# USB_USB2SS_GBL_3100C100h register map
Vendor: Texas Instruments
Registers are 32-bit, read-write, reset 0x0 unless marked. A register's access mark holds for its fields unless they carry their own. Offsets are as the file gives them; [hi:lo] are bit positions; lines under a group give offsets from that group; 'fields as' and 'values as' point back to an identical list; <NAME> marks a mode.

## USB2SS_GBL (part 4 of 4)
0x1C0 USB2SS_GBL_GPIPE access not given reset not defined
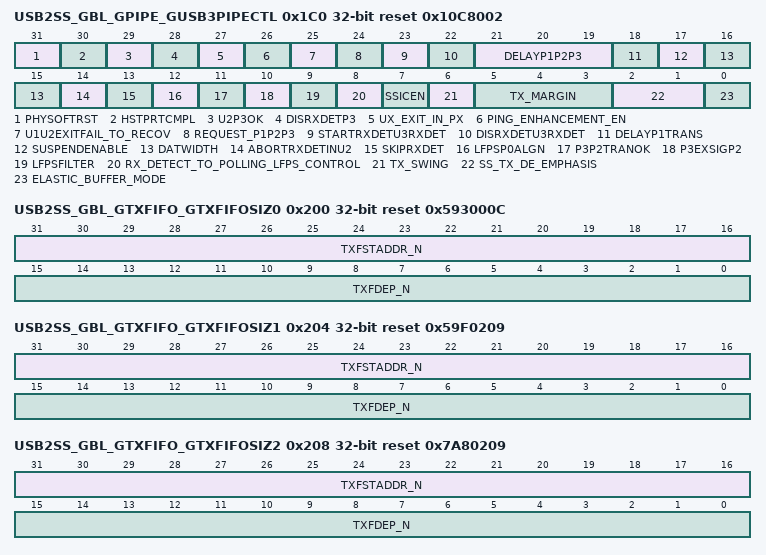
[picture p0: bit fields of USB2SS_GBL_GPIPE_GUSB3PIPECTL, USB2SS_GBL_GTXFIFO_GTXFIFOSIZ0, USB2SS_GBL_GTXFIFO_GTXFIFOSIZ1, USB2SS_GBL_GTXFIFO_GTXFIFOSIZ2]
0x1C0 USB2SS_GBL_GPIPE_GUSB3PIPECTL access per field reset 0x10C8002 — Global USB 3.0 PIPE Control RegisterThe application uses this register to configure the USB3 PHY and PIPE interface.Device-only configuration requires only one register. In Host mode, registers are implemented for each port.For more details on GUSB3PIPECTL(#n) bits, refer to section 'GUSB3PIPECTLn Register' in the User Guide.Note: - GUSB3PIPECTLn registers are not applicable for USB 2.0-only mode.
  [31] PHYSOFTRST rw — USB3 PHY Soft Reset After setting this bit to '1', the software needs to clear this bit. For more information, refer to Figure 'Software Resets and PHY Clock Sequencing and Requirements' in the Databook. Reset Source: rst_mod_g_rst_n
  [30] HSTPRTCMPL rw — HstPrtCmplThis feature tests the PIPE PHY compliance patterns without having to have a test fixture on the USB 3.0 cable. This bit enables placing the SS port link into a compliance state. By default, this bit must be set to 1'b0.In compliance lab testing, the SS port link enters compliance after failing the first polling sequence after power on. Set this bit to 0, when you run compliance tests.The sequence for using this functionality is as follows: - 1. Disconnect any plugged in devices. - 2. Perform USBCMD.HCRST or power-on-chip reset. - 3. Set PORTSC.PLS=0xA. - 4. Set PORTSC.PP=0. - 5. Set GUSB3PIPECTL. HstPrtCmpl=1. This places the link into compliance state.To advance the compliance pattern, follow this sequence [toggle the set GUSB3PIPECTL. HstPrtCmpl]: - 1. Set GUSB3PIPECTL.HstPrtCmpl=0. - 2. Set GUSB3PIPECTL.HstPrtCmpl=1. This advances the link to the next compliance pattern.To exit from the compliance state perform USBCMD.HCRST or power-on-chip reset. Reset Source: rst_mod_g_rst_n
  [29] U2P3OK rw — P3 OK for SSInactive [SSIP3ok] - 0: During link state SS.Inactive, put PHY in P2 [Default] - 1: During link state SS.Inactive, put PHY in P3. Reset Source: rst_mod_g_rst_n
  [28] DISRXDETP3 rw — Disabled receiver detection in P3 [DisRxDetP3] - 0: If PHY is in P3 and controller needs to perform receiver detection, The controller performs receiver detection in P3. [Default] - 1: If PHY is in P3 and controller needs to perform receiver detection, The controller changes the PHY power state to P2 and then performs receiver detection. After receiver detection, the cores changes PHY power state to P3. Reset Source: rst_mod_g_rst_n
  [27] UX_EXIT_IN_PX rw — Ux Exit in Px [Ux_exit_in_Px] - 0: The controller does U1/U2/U3 exit in PHY power state P0 [default behavior]. - 1: The controller does U1/U2/U3 exit in PHY power state P1/P2/P3 respectively. Note: This bit is used by third-party SS PHY. It must be set to '0' for Synopsys PHY. Reset Source: rst_mod_g_rst_n
  [26] PING_ENHANCEMENT_EN rw — Ping Enhancement Enable [ping_enhancement_en]When set, the Downstream port U1 ping receive timeout becomes 500 ms instead of 300 ms. Minimum Ping.LFPS receive duration is 8 ns [one mac3_clk]. This field is valid for the downstream port only. Note: This bit is used by third-party SS PHY. It must be set to '0' for Synopsys PHY. Reset Source: rst_mod_g_rst_n
  [25] U1U2EXITFAIL_TO_RECOV rw — U1U2exitfail to Recovery [u1u2exitfail_to_recov]When set, and U1/U2 LFPS handshake fails, the LTSSM transitions from U1/U2 to Recovery instead of SS Inactive. If Recovery fails, then the LTSSM can enter SS.Inactive. This is an enhancement only. It prevents interoperability issue if the remote link does not do proper handshake. Reset Source: rst_mod_g_rst_n
  [24] REQUEST_P1P2P3 rw — Always Request P1/P2/P3 for U1/U2/U3 [request_p1p2p3]When set, the controller always requests PHY power change from P0 to P1/P2/P3 during U0 to U1/U2/U3 transition.If this bit is 0, and immediate Ux exit [remotely initiated, or locally initiated] happens, the controller does not request P1/P2/P3 power state change.Note: This bit must be set to '1' for Synopsys PHY. For third-party SS PHY, check with your PHY vendor. Reset Source: rst_mod_g_rst_n
  [23] STARTRXDETU3RXDET wo — Start Receiver Detection in U3/Rx.Detect [StartRxdetU3RxDet]If DWC_USB3_GUSB3PIPECTL_INIT[22] is set, and the link is in either U3 or Rx.Detect state, the controller starts receiver detection on the rising edge of this bit. This can only be used for Downstream ports. This bit must be set to '0' for Upstream ports. This feature must not be enabled for normal operation. If have to use this feature, contact Synopsys. Reset Source: rst_mod_g_rst_n
  [22] DISRXDETU3RXDET rw — Disable Receiver Detection in U3/Rx.DetWhen set, the controller does not handle receiver detection in either U3 or Rx.Detect states. DWC_USB3_GUSB3PIPECTL_INIT[23] must be used to start receiver detection manually. This bit can only be used for the downstream port. This bit must be set to '0' for Upstream ports. This feature must not be enabled for normal operation. If you have to use this feature, contact Synopsys. Reset Source: rst_mod_g_rst_n
  [21:19] DELAYP1P2P3 rw — Delay P1P2P3Delay P0 to P1/P2/P3 request when entering U1/U2/U3 until [DWC_USB3_GUSB3PIPECTL_INIT[21:19]*8] 8B10B error occurs, or Pipe3_RxValid drops to 0.DWC_USB3_GUSB3PIPECTL_INIT[18] must be 1 to enable this functionality. Reset Source: rst_mod_g_rst_n
  [18] DELAYP1TRANS rw — Delay PHY power change from P0 to P1/P2/P3 when link state changing from U0 to U1/U2/U3 respectively. - 1'b1: When entering U1/U2/U3, delay the transition to P1/P2/P3 until the pipe3 signals, Pipe3_RxElecIdle is 1 and pipe3_RxValid is 0 - 1'b0: When entering U1/U2/U3, transition to P1/P2/P3 without checking for Pipe3_RxElecIdle and pipe3_RxValid.Note: - If you are using Synopsys PHY, contact Synopsys Customer Support for recommendation on setting this bit because it is node dependent. - If you are using a third-party SS PHY, check with your PHY vendor for recommendation on setting this bit. Reset Source: rst_mod_g_rst_n
  [17] SUSPENDENABLE rw — Suspend USB3.0 SS PHY [Suspend_en]When set, and if Suspend conditions are valid, the USB 3.0 PHY enters Suspend mode.For DRD configurations, it is recommended that this bit is set to '0' during coreConsultant configuration. If it is set to '1', then the application must clear this bit after power-on reset. Application needs to set it to '1' after the controller initialization is completed.For all other configurations, this bit can be set to '1' during controller configuration. Reset Source: rst_mod_g_rst_n
  [16:15] DATWIDTH ro — PIPE Data Width [DatWidth] - 2'b00: 32 bits - 2'b01: 16 bitsOne clock after reset, these bits receive the value seen on the pipe3_DataBusWidth. The simulation testbench uses the coreConsultant parameter to configure the VIP. These bits in the coreConsultant parameter must match your PHY data width and the pipe3_DataBusWidth port.Note: 8-bit data width is not supported. Reset Source: rst_mod_g_rst_n
  [14] ABORTRXDETINU2 rw — Abort Rx Detect in U2 [AbortRxDetInU2]When set and the link state is U2, the controller will abort receiver detection if it receives U2 exit LFPS from the remote link partner. This bit is for the downstream port only.Note: This bit is used by third-party SS PHY. It must be set to '0' for Synopsys PHY. Reset Source: rst_mod_g_rst_n
  [13] SKIPRXDET rw — Skip Rx Detect:When set, the controller skips Rx Detection if pipe3_RxElecIdle is low. Skip is defined as waiting for the appropriate timeout, then repeating the operation. Reset Source: rst_mod_g_rst_n
  [12] LFPSP0ALGN rw — LFPS P0 Align:When set, - The controller deasserts LFPS transmission on the clock edge that it requests Phy power state 0 when exiting U1, U2, or U3 low power states. Otherwise, LFPS transmission is asserted one clock earlier. - The controller requests symbol transmission two pipe3_rx_pclks periods after the PHY asserts PhyStatus as a result of the PHY switching from P1 or P2 state to P0 state.Currently, this bit is only used in USB 3.0 HUB with Synopsys PHY. For other USB 3.0 Host, Device, and DRD cores, this bit is not required. Reset Source: rst_mod_g_rst_n
  [11] P3P2TRANOK rw — P3 P2 Transitions OK [P3P2TranOK]When set, the controller transitions directly from Phy power state P2 to P3 or from state P3 to P2.When not set, P0 is always entered as an intermediate state during transitions between P2 and P3, as defined in the PIPE3 Specification.According to the PIPE3 Specification, any direct transition between P3 and P2 is illegal.Note: This bit is used by third-party SS PHY. It must be set to '0' for Synopsys PHY. Reset Source: rst_mod_g_rst_n
  [10] P3EXSIGP2 rw — P3 Exit Signal in P2 [P3ExSigP2]When this bit is set, the controller always changes the PHY power state to P2, before attempting a U3 exit handshake. This bit is used only for some non-Synopsys PHYs that cannot do LFPS in P3.Note: This bit is used by third-party SS PHY. It must be set to '0' for Synopsys PHY. Reset Source: rst_mod_g_rst_n
  [9] LFPSFILTER rw — LFPS Filter [LFPSFilt]When set, filter LFPS reception with pipe3_RxValid in PHY power state P0, that is, ignore LFPS reception from the PHY unless both pipe3_Rxelecidle and pipe3_RxValid are deasserted. Reset Source: rst_mod_g_rst_n
  [8] RX_DETECT_TO_POLLING_LFPS_CONTROL rw — RX_DETECT to Polling.LFPS Control - 1'b0 [Default]: Enables a 400us delay to start Polling LFPS after RX_DETECT. This allows VCM offset to settle to a proper level. - 1'b1: Disables the 400us delay to start Polling LFPS after RX_DETECT.During controller certification with third party PHY it is observed that the PHY is not able to meet the Tx AC common mode voltage active [VTX-CM-ACPP_ACTIVE <100mv] if the link starts polling within 80us from the time rx.detect is performed.To meet this VTX-CM-ACPP_ACTIVE specification, the polling must be delayed further. If the PHY does not have issue then they can set this bit to 1 which allows polling to start within 80us. Reset Source: rst_mod_g_rst_n
  [7] SSICEN rw — This field is not used. Reset Source: rst_mod_g_rst_n
  [6] TX_SWING rw — Tx Swing [TxSwing]Refer to the PIPE3 specification. Reset Source: rst_mod_g_rst_n
  [5:3] TX_MARGIN rw — Tx Margin[2:0] [TxMargin]Refer to Table 5-3 of the PIPE3 Specification. Reset Source: rst_mod_g_rst_n
  [2:1] SS_TX_DE_EMPHASIS rw — Tx Deemphasis [TxDeemphasis]The value driven to the PHY is controlled by the LTSSM during USB3 Compliance mode.[Refer to Table 5-3 of the PIPE3 specification.] Reset Source: rst_mod_g_rst_n
  [0] ELASTIC_BUFFER_MODE rw — Elastic Buffer Mode [ElasticBufferMode][Refer to Table 5-3 of the PIPE3 specification.] Reset Source: rst_mod_g_rst_n
0x200 USB2SS_GBL_GTXFIFO access not given reset not defined
0x200 USB2SS_GBL_GTXFIFO_GTXFIFOSIZ0 reset 0x593000C — Global Transmit FIFO Size RegisterThis register specifies the RAM start address and depth (both in MDWIDTH-bit words) for each implemented TxFIFO. The number of TxFIFOs depends on the configuration parameters including the number of Device IN Endpoints, number of Host Bus Instances, and presence of Debug Capability.The register default values for each mode are assigned in coreConsultant based on the maximum packet size, number of packets to be buffered, speed of host bus instance, bus latency, and mode of operation (host, device, or, DBC). Upon reset and mode transitions, hardware automatically programs these registers to the default values. Consequently, there is typically no need for the software to modify the pre-defined default values.For the debug capability mode, the currently mapped EP0 IN and EP1 IN TxFIFO numbers can be read from the GFIFOPRIDBC register. For more details on the usage of the GTXFIFOSIZn and GRXFIFOSIZn registers for different modes of operation, refer to 'Memory Requirements' chapter in the Databook.
  [31:16] TXFSTADDR_N — Transmit FIFOn RAM Start Address This field contains the memory start address for TxFIFOn in MDWIDTH-bit words. Reset Source: rst_mod_g_rst_n
  [15:0] TXFDEP_N — TxFIFO Depth This field contains the depth of TxFIFOn in MDWIDTH-bit words. - Minimum value: 32 - Maximum value: 32,768For more information, see 'Integrating the Controller' chapter in the User Guide. Reset Source: rst_mod_g_rst_n
0x204 USB2SS_GBL_GTXFIFO_GTXFIFOSIZ1 reset 0x59F0209 — Register GTXFIFOSIZ 1
  [31:16] TXFSTADDR_N — Transmit FIFOn RAM Start Address This field contains the memory start address for TxFIFOn in MDWIDTH-bit words. Reset Source: rst_mod_g_rst_n
  [15:0] TXFDEP_N — TXFDEP_N Reset Source: rst_mod_g_rst_n
0x208 USB2SS_GBL_GTXFIFO_GTXFIFOSIZ2 reset 0x7A80209 — Transmit FIFOn RAM Start Address This field contains the memory start address for TxFIFOn in MDWIDTH-bit words.
  fields as USB2SS_GBL_GTXFIFO_GTXFIFOSIZ0
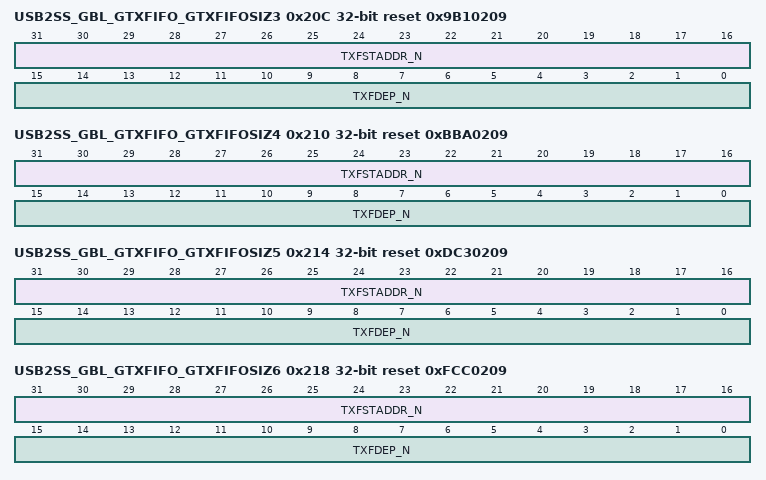
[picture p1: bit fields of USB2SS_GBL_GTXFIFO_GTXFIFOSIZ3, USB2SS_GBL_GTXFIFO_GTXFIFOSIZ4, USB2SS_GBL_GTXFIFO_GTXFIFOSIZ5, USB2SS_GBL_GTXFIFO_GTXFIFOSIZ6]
0x20C USB2SS_GBL_GTXFIFO_GTXFIFOSIZ3 reset 0x9B10209 — Register GTXFIFOSIZ 3
  [31:16] TXFSTADDR_N — Transmit FIFOn RAM Start AddressThis field contains the memory start address for TxFIFOn in MDWIDTH-bit words. Reset Source: rst_mod_g_rst_n
  [15:0] TXFDEP_N — TXFDEP_N: TxFIFO Depth [TxFDep_n]This field contains the depth of TxFIFOn in MDWIDTH-bit words. - Minimum value: 32 - Maximum value: 32,768For more information, see 'Integrating the Controller' chapter in the User Guide. Reset Source: rst_mod_g_rst_n
0x210 USB2SS_GBL_GTXFIFO_GTXFIFOSIZ4 reset 0xBBA0209 — Register GTXFIFOSIZ 4
  [31:16] TXFSTADDR_N — TXFSTADDR_N Reset Source: rst_mod_g_rst_n
  [15:0] TXFDEP_N — TXFDEP_N: TxFIFO Depth [TxFDep_n]This field contains the depth of TxFIFOn in MDWIDTH-bit words. - Minimum value: 32 - Maximum value: 32,768For more information, see 'Integrating the Controller' chapter in the User Guide. Reset Source: rst_mod_g_rst_n
0x214 USB2SS_GBL_GTXFIFO_GTXFIFOSIZ5 reset 0xDC30209 — Register GTXFIFOSIZ 5
  [31:16] TXFSTADDR_N — Transmit FIFOn RAM Start Address Reset Source: rst_mod_g_rst_n
  [15:0] TXFDEP_N — TxFIFO Depth This field contains the depth of TxFIFOn in MDWIDTH-bit words. - Minimum value: 32 - Maximum value: 32,768For more information, see 'Integrating the Controller' chapter in the User Guide. Reset Source: rst_mod_g_rst_n
0x218 USB2SS_GBL_GTXFIFO_GTXFIFOSIZ6 reset 0xFCC0209 — Register GTXFIFOSIZ 6
  fields as USB2SS_GBL_GTXFIFO_GTXFIFOSIZ0
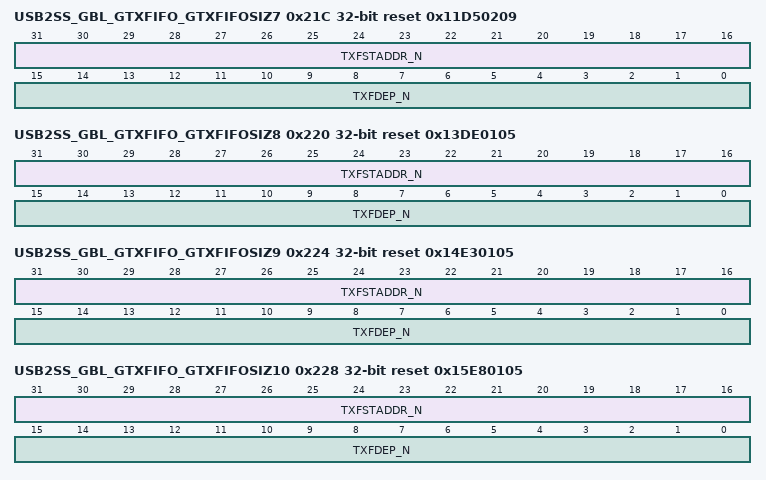
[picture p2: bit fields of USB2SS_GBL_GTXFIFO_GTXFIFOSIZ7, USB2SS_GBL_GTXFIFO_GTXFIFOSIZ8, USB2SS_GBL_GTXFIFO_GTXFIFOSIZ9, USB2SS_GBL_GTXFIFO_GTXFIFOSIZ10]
0x21C USB2SS_GBL_GTXFIFO_GTXFIFOSIZ7 reset 0x11D50209 — Register GTXFIFOSIZ 7
  [31:16] TXFSTADDR_N — Transmit FIFOn RAM Start Address This field contains the memory start address for TxFIFOn in MDWIDTH-bit words. Reset Source: rst_mod_g_rst_n
  [15:0] TXFDEP_N — TXFDEP_NThis field contains the depth of TxFIFOn in MDWIDTH-bit words. - Minimum value: 32 - Maximum value: 32,768For more information, see 'Integrating the Controller' chapter in the User Guide. Reset Source: rst_mod_g_rst_n
0x220 USB2SS_GBL_GTXFIFO_GTXFIFOSIZ8 reset 0x13DE0105 — Register GTXFIFOSIZ 8
  fields as USB2SS_GBL_GTXFIFO_GTXFIFOSIZ0
0x224 USB2SS_GBL_GTXFIFO_GTXFIFOSIZ9 reset 0x14E30105 — Register GTXFIFOSIZ 9
  fields as USB2SS_GBL_GTXFIFO_GTXFIFOSIZ0
0x228 USB2SS_GBL_GTXFIFO_GTXFIFOSIZ10 reset 0x15E80105 — GTXFIFOSIZ 10
  [31:16] TXFSTADDR_N — Transmit FIFOn RAM Start Address This field contains the memory start address for TxFIFOn in MDWIDTH-bit words. Reset Source: rst_mod_g_rst_n
  [15:0] TXFDEP_N — TXFDEP_N: TxFIFO Depth [TxFDep_n]This field contains the depth of TxFIFOn in MDWIDTH-bit words. - Minimum value: 32 - Maximum value: 32,768For more information, see 'Integrating the Controller' chapter in the User Guide. Reset Source: rst_mod_g_rst_n
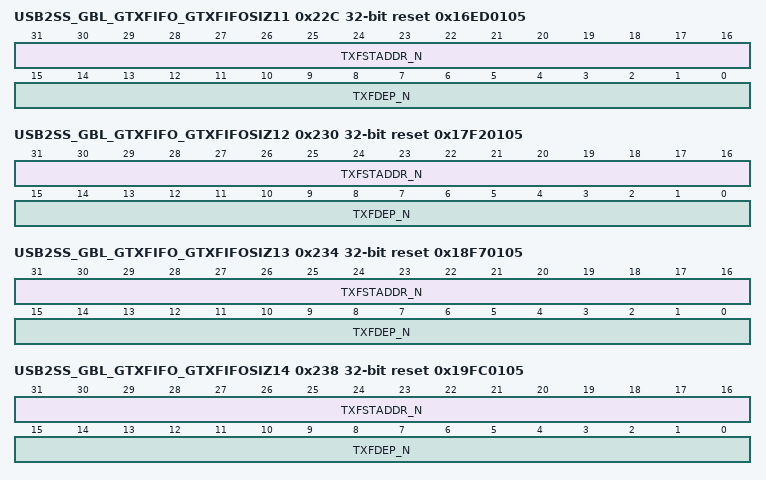
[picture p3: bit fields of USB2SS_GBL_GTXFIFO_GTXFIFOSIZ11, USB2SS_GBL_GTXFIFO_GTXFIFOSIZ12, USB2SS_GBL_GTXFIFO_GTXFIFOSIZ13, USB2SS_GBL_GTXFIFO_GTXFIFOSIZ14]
0x22C USB2SS_GBL_GTXFIFO_GTXFIFOSIZ11 reset 0x16ED0105 — Register GTXFIFOSIZ 11
  [31:16] TXFSTADDR_N — Transmit FIFOn RAM Start AddressThis field contains the memory start address for TxFIFOn in MDWIDTH-bit words. Reset Source: rst_mod_g_rst_n
  [15:0] TXFDEP_N — TxFIFO Depth This field contains the depth of TxFIFOn in MDWIDTH-bit words. - Minimum value: 32 - Maximum value: 32,768For more information, see 'Integrating the Controller' chapter in the User Guide. Reset Source: rst_mod_g_rst_n
0x230 USB2SS_GBL_GTXFIFO_GTXFIFOSIZ12 reset 0x17F20105 — GTXFIFOSIZ 12
  fields as USB2SS_GBL_GTXFIFO_GTXFIFOSIZ0
0x234 USB2SS_GBL_GTXFIFO_GTXFIFOSIZ13 reset 0x18F70105 — Register GTXFIFOSIZ 13
  fields as USB2SS_GBL_GTXFIFO_GTXFIFOSIZ1
0x238 USB2SS_GBL_GTXFIFO_GTXFIFOSIZ14 reset 0x19FC0105 — Register GTXFIFOSIZ 14
  fields as USB2SS_GBL_GTXFIFO_GTXFIFOSIZ1
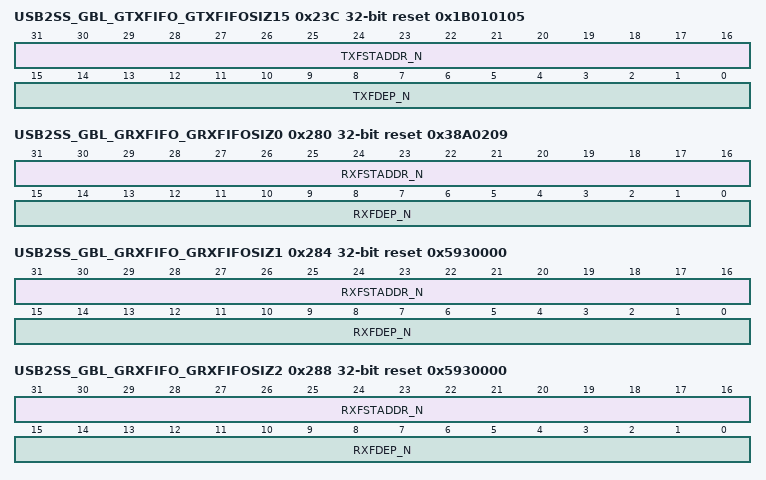
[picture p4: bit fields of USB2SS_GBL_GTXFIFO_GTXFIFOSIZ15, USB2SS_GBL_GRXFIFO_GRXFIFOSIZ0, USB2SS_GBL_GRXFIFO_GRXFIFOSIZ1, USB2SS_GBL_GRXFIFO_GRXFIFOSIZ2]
0x23C USB2SS_GBL_GTXFIFO_GTXFIFOSIZ15 reset 0x1B010105 — Register GTXFIFOSIZ 15
  [31:16] TXFSTADDR_N — TXFSTADDR_N Reset Source: rst_mod_g_rst_n
  [15:0] TXFDEP_N — TXFDEP_N Reset Source: rst_mod_g_rst_n
0x280 USB2SS_GBL_GRXFIFO access not given reset not defined
0x280 USB2SS_GBL_GRXFIFO_GRXFIFOSIZ0 reset 0x38A0209 — Global Receive FIFO Size RegisterThis register specifies the RAM start address and depth (both in MDWIDTH-bit words) for each implemented RxFIFO. The number of RxFIFOs depends on the configuration parameters including the number of Host Bus Instances and presence of Debug Capability. device mode requires only one RxFIFO.The register default values for each mode are assigned in coreConsultant based on the maximum packet size, number of packets to be buffered, speed of the host bus instance, bus latency, and mode of operation (host, device, or DBC). Upon reset and mode transitions, hardware automatically programs these registers to the default values. Consequently, there is typically no need for the software to modify the pre-defined default values.For the debug capability mode, the currently mapped RxFIFO number can be read from the GFIFOPRIDBC register.For more details on the usage of the GTXFIFOSIZn and GRXFIFOSIZn registers for different modes of operation, refer to 'Memory Requirements' chapter in the Databook.
  [31:16] RXFSTADDR_N — RxFIFOn RAM Start Address [RxFStAddr_n]This field contains the memory start address for RxFIFOn in MDWIDTH-bit words. Reset Source: rst_mod_g_rst_n
  [15:0] RXFDEP_N — RxFIFO Depth [RxFDep_n]This field contains the depth of RxFIFOn in MDWIDTH-bit words. - Minimum value: 32 - Maximum value: 16,384 Reset Source: rst_mod_g_rst_n
0x284 USB2SS_GBL_GRXFIFO_GRXFIFOSIZ1 reset 0x5930000 — Register
  [31:16] RXFSTADDR_N — RXFSTADDR_N Reset Source: rst_mod_g_rst_n
  [15:0] RXFDEP_N — RxFIFO Depth This field contains the depth of RxFIFOn in MDWIDTH-bit words. - Minimum value: 32 - Maximum value: 16,384 Reset Source: rst_mod_g_rst_n
0x288 USB2SS_GBL_GRXFIFO_GRXFIFOSIZ2 reset 0x5930000 — Register
  [31:16] RXFSTADDR_N — RAM Start Address This field contains the memory start address for RxFIFOn in MDWIDTH-bit words. Reset Source: rst_mod_g_rst_n
  [15:0] RXFDEP_N — RxFIFO Depth This field contains the depth of RxFIFOn in MDWIDTH-bit words. - Minimum value: 32 - Maximum value: 16,384 Reset Source: rst_mod_g_rst_n
0x300 USB2SS_GBL_GEVNT_GEVNTADRLO_j — Global Event Buffer Address (Low) RegisterThis is an alternate register for the GEVNTADRn register.
  [31:0] EVNTADRLO — Event Buffer Address [EvntAdrLo]Holds the lower 32 bits of start address of the external memory for the Event Buffer. During operation, hardware does not update this address. Reset Source: rst_mod_g_rst_n
0x304 USB2SS_GBL_GEVNT_GEVNTADRHI_j — Global Event Buffer Address (High) RegisterThis is an alternate register for the GEVNTADRn register.
  [31:0] EVNTADRHI — Event Buffer Address [EvntAdrHi]Holds the higher 32 bits of start address of the external memory for the Event Buffer. During operation, hardware does not update this address. Reset Source: rst_mod_g_rst_n
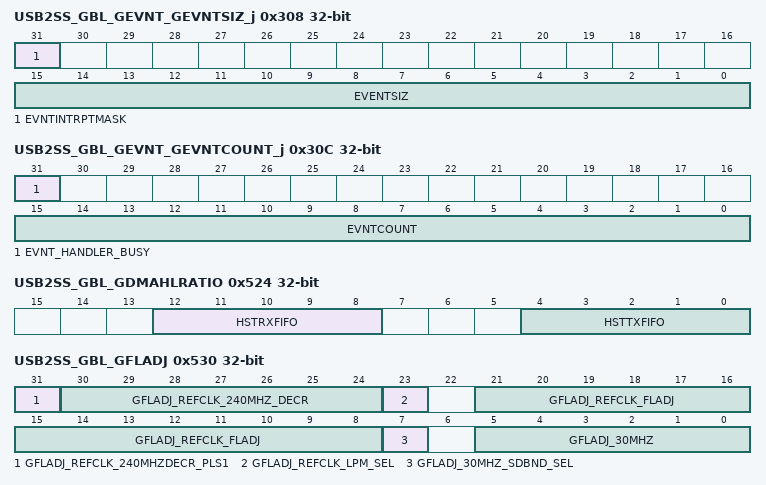
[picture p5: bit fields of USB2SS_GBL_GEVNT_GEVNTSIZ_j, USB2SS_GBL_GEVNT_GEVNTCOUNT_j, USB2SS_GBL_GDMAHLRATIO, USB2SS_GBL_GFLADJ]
0x308 USB2SS_GBL_GEVNT_GEVNTSIZ_j — Global Event Buffer Size RegisterThis register holds the Event Buffer Size and the Event Interrupt Mask bit. During power-on initialization, software must initialize the size with the number of bytes allocated for the Event Buffer. The Event Interrupt Mask will mask the interrupt, but events are still queued. After configuration, software must preserve the Event Buffer Size value when changing the Event Interrupt Mask.
  [31] EVNTINTRPTMASK — Event Interrupt Mask [EvntIntMask].When set to '1', this prevents the interrupt from being generated. However, even when the mask is set, the events are queued. Reset Source: rst_mod_g_rst_n
  [15:0] EVENTSIZ — Event Buffer Size in bytes [EVNTSiz]Holds the size of the Event Buffer in bytes. must be a multiple of four. This is programmed by software once during initialization.The minimum size of the event buffer is 32 bytes. Reset Source: rst_mod_g_rst_n
0x30C USB2SS_GBL_GEVNT_GEVNTCOUNT_j — Global Event Buffer Count RegisterThis register holds the number of valid bytes in the Event Buffer. During initialization, software must initialize the count by writing 0 to the Event Count field. Each time the hardware writes a new event to the Event Buffer, it increments this count. Most events are four bytes, but some events may span over multiple four byte entries. Whenever the count is greater than zero and if enabled, conditions for interrupt moderation are satisfied, the hardware raises the corresponding interrupt line (depending on the EvntIntMask bit in the GEVNTSIZn register). On an interrupt, software processes one or more events out of the Event Buffer. Afterwards, software must write the Event Count field with the number of bytes it processed. If Interrupt Moderation is enabled, then software needs to clear EVNT_HANDLER_BUSY bit. Clock crossing delays may result in the continuous assertion of the interrupt after software acknowledges the last event. Therefore, when the interrupt line is asserted, software must read the GEVNTCOUNT register and only process events if the GEVNTCOUNT is greater than 0.
  [31] EVNT_HANDLER_BUSY — Event Handler BusyDevice software event handler busy indication. The controller sets this bit when the interrupt line is asserted due to pending events. Software clears this bit [with 1'b1] when it has finished processing the events [along with updating the EVNTCOUNT in this register]. The controller does not raise the interrupt line for a new event unless this bit is cleared.Note: When Interrupt moderation is disabled [that is, DEVICE_IMODI = 0], this bit is ignored. Reset Source: rst_mod_g_rst_n
  [15:0] EVNTCOUNT — Event Count [EVNTCount]When read, returns the number of valid events in the Event Buffer [in bytes].When written, hardware decrements the count by the value written.When Interrupt moderation is enabled [that is, DEVICE_IMODI!= 0], the interrupt line gets de-asserted when the first write happens on this register to decrement the count. When Interrupt moderation is disabled [that is, DEVICE_IMODI = 0], the Interrupt line continues to get asserted until the event count becomes zero [no-moderation behavior]. Reset Source: rst_mod_g_rst_n
0x500 USB2SS_GBL_GHWPARAMS8 ro reset 0x660 — Global Hardware Parameters Register 8This register contains the hardware configuration options that you can select in the coreConsultant GUI. For a description of each parameter, refer to the 'Parameter Descriptions' chapter in the Databook. This information is also available in coreConsultant by right-clicking the parameter label and selecting 'What's This' or by clicking the Help tab. Note: Some of the global hardware parameters are not currently modifiable in coreConsultant. These settings are in the <workspace>/src/DWC_usb3_params.v file. you must not change them.
  [31:0] GHWPARAMS8_32_0 — DWC_USB3_DCACHE_DEPTH_INFO Reset Source: rst_mod_g_rst_n
0x50C USB2SS_GBL_GUCTL3 — Global User Control Register 3This register provides a few options for the software to control the controller behavior in the Host mode. Most of the options are used to improve host inter-operability with different devices.
  [16] SCH_PING_EARLY — Enable SuperSpeed Ping Transaction Packet scheduling early in the microframe.This bit is valid in Host mode only. Reset Source: rst_mod_g_rst_n
0x510 USB2SS_GBL_GTXFIFOPRIDEV — Global Device TX FIFO DMA Priority RegisterThis register specifies the relative DMA priority level among the Device TXFIFOs (one per IN endpoint). Each register bit[n] controls the priority (1: high, 0: low) of each TXFIFO[n]. When multiple TXFIFOs compete for DMA service at a given time (that is, multiple TXQs contain TX DMA requests and their corresponding TXFIFOs have space available), the TX DMA arbiter grants access on a packet-basis in the following manner: - 1. High-priority TXFIFOs are granted access using round-robin arbitration - 2. Low-priority TXFIFOs are granted access using round-robin arbitration only after the high-priority TXFIFOs have no further processing to do (that is, either the TXQs are empty or the corresponding TXFIFOs are full).For scatter-gather packets, the arbiter grants successive DMA requests to the same FIFO until the entire packet is completed.When configuring periodic IN endpoints, software must set register bit[n]=1, where n is the TXFIFO assignment. This ensures that the DMA for isochronous or interrupt IN endpoints are prioritized over bulk or control IN endpoints.This register is present only when the controller is configured to operate in the device mode (includes DRD mode). The register size corresponds to the number of Device IN endpoints.Note - Since the device mode uses only one RXFIFO, there is no Device RXFIFO DMA Priority Register.
  [15:0] GTXFIFOPRIDEV — Device TxFIFO priority Reset Source: rst_mod_g_rst_n
0x518 USB2SS_GBL_GTXFIFOPRIHST — Global Host TX FIFO DMA Priority RegisterThis register specifies the relative DMA priority level among the Host TXFIFOs (one per USB bus instance) within the associated speed group (SS or HS/FSLS). Each register bit[n] controls the priority (1: high, 0: low) of TXFIFO[n] within a speed group. When multiple TXFIFOs compete for DMA service at a given time (i.e., multiple TXQs contain TX DMA requests and their corresponding TXFIFOs have space available), the TX DMA arbiter grants access on a packet-basis in the following manner: - 1. Among the FIFOs in the same speed group (SS or HS/FSLS): a. High-priority TXFIFOs are granted access using round-robin arbitration b. Low-priority TXFIFOs are granted access using round-robin arbitration only after the high-priority TXFIFOs have no further processing to do (that is, either the TXQs are empty or the corresponding TXFIFOs are full). - 2. The TX DMA arbiter prioritizes the SS speed group or HS/FSLS speed group according to the ratio programmed in the GDMAHLRATIO register.For scatter-gather packets, the arbiter grants successive DMA requests to the same FIFO until the entire packet is completed.This register is present only when the controller is configured to operate in the host mode (includes DRD mode). The register size corresponds to the number of configured USB bus instances. for example, in the default configuration, there are 3 USB bus instances (1 SS, 1 HS, and 1 FSLS).
  [2:0] GTXFIFOPRIHST — Host TxFIFO priority Reset Source: rst_mod_g_rst_n
0x51C USB2SS_GBL_GRXFIFOPRIHST — Global Host RX FIFO DMA Priority RegisterThis register specifies the relative DMA priority level among the Host RXFIFOs (one per USB bus instance) within the associated speed group (SS or HS/FSLS). Each register bit[n] controls the priority (1: high, 0: low) of RXFIFO[n] within a speed group. When multiple RXFIFOs compete for DMA service at a given time (i.e., multiple RXQs contain RX DMA requests and their corresponding RXFIFOs have data available), the RX DMA arbiter grants access on a packet-basis in the following manner: - 1. Among the FIFOs in the same speed group (SS or HS/FSLS): a. High-priority RXFIFOs are granted access using round-robin arbitration b. Low-priority RXFIFOs are granted access using round-robin arbitration only after high-priority RXFIFOs have no further processing to do (that is, either the RXQs are empty or the corresponding RXFIFOs do not have the required data). - 2. The RX DMA arbiter prioritizes the SS speed group or HS/FSLS speed group according to the ratio programmed in the GDMAHLRATIO register.For scatter-gather packets, the arbiter grants successive DMA requests to the same FIFO until the entire packet is completed.This register is present only when the controller is configured to operate in the host mode (includes DRD mode). The register size corresponds to the number of configured USB bus instances. for example, in the default configuration, there are 3 USB bus instances (1 SS, 1 HS, and 1 FSLS).
  [2:0] GRXFIFOPRIHST — Host RxFIFO priority Reset Source: rst_mod_g_rst_n
0x524 USB2SS_GBL_GDMAHLRATIO — Global Host FIFO DMA High-Low Priority Ratio RegisterThis register specifies the relative priority of the SS FIFOs with respect to the HS/FSLS FIFOs. The DMA arbiter prioritizes the HS/FSLS round-robin arbiter group every DMA High-Low Priority Ratio grants as indicated in the register separately for TX and RX.To illustrate, consider that all FIFOs are requesting access simultaneously, and the ratio is 4. SS gets priority for 4 packets, HS/FSLS gets priority for 1 packet, SS gets priority for 4 packets, HS/FSLS gets priority for 1 packet, and so on.If FIFOs from both speed groups are not requesting access simultaneously then, - if SS got grants 4 out of the last 4 times, then HS/FSLS get the priority on any future request. - if HS/FSLS got the grant last time, SS gets the priority on the next request. - if there is a valid request on either SS or HS/FSLS, a grant is always awarded. there is no idle.This register is present if the controller is configured to operate in host mode (includes DRD).
  [12:8] HSTRXFIFO — Host RXFIFO DMA High-Low Priority Reset Source: rst_mod_g_rst_n
  [4:0] HSTTXFIFO — Host TXFIFO DMA High-Low Priority Reset Source: rst_mod_g_rst_n
0x530 USB2SS_GBL_GFLADJ access per field — Global Frame Length Adjustment RegisterThis register provides options for the software to control the controller behavior with respect to SOF (Start of Frame) and ITP (Isochronous Timestamp Packet) timers and frame timer functionality. It provides an option to override the fladj_30mhz_reg sideband signal. In addition, it enables running SOF or ITP frame timer counters completely from the ref_clk. This facilitates hardware LPM in host mode with the SOF or ITP counters being run from the ref_clk signal.
  [31] GFLADJ_REFCLK_240MHZDECR_PLS1 rw — GFLADJ_REFCLK_240MHZDECR_PLS1This field indicates that the decrement value that the controller applies for each ref_clk must be GFLADJ_REFCLK_240MHZ_DECR and GFLADJ_REFCLK_240MHZ_DECR +1 alternatively on each ref_clk.Set this bit to a '1' only if GFLADJ_REFCLK_LPM_SEL is set to '1' and the fractional component of 240/ref_frequency is greater than or equal to 0.5. Examples:If the ref_clk is 19.2 MHz then - GUCTL.REF_CLK_PERIOD = 52 - GFLADJ.GFLADJ_REFCLK_240MHZ_DECR = [240/19.2] = 12.5 - GFLADJ.GFLADJ_REFCLK_240MHZDECR_PLS1 = 1If the ref_clk is 24 MHz then - GUCTL.REF_CLK_PERIOD = 41 - GFLADJ.GFLADJ_REFCLK_240MHZ_DECR = [240/24] = 10 - GFLADJ.GFLADJ_REFCLK_240MHZDECR_PLS1 = 0 Reset Source: rst_mod_g_rst_n
  [30:24] GFLADJ_REFCLK_240MHZ_DECR rw — This field indicates the decrement value that the controller applies for each ref_clk in order to derive a frame timer in terms of a 240-MHz clock. This field must be programmed to a non-zero value only if GFLADJ_REFCLK_LPM_SEL is set to '1'.The value is derived as follows:GFLADJ_REFCLK_240MHZ_DECR = 240/ref_clk_frequencyExamples:If the ref_clk is 24 MHz then - GUCTL.REF_CLK_PERIOD = 41 - GFLADJ.GFLADJ_REFCLK_240MHZ_DECR = 240/24 = 10If the ref_clk is 48 MHz then - GUCTL.REF_CLK_PERIOD = 20 - GFLADJ.GFLADJ_REFCLK_240MHZ_DECR = 240/48 = 5If the ref_clk is 17 MHz then - GUCTL.REF_CLK_PERIOD = 58 - GFLADJ.GFLADJ_REFCLK_240MHZ_DECR = 240/17 = 14 Reset Source: rst_mod_g_rst_n
  [23] GFLADJ_REFCLK_LPM_SEL rw — This bit enables the functionality of running SOF/ITP counters on the ref_clk. This bit must not be set to '1' if GCTL.SOFITPSYNC bit is set to '1'. Similarly, if GFLADJ_REFCLK_LPM_SEL set to '1', GCTL.SOFITPSYNC must not be set to '1'. In device mode, setting this bit to '1' enables SOF tracking using ref_clk.When GFLADJ_REFCLK_LPM_SEL is set to '1' the overloading of the suspend control of the USB 2.0 first port PHY [UTMI/ULPI] with USB 3.0 port states is removed.For example, for Synopsys PHY, the COMMONONN signal can be tied to '1'. Note that the ref_clk frequencies supported in this mode are 16/17/19.2/20/24/39.7/40 MHz. The utmi_clk[0] signal of the controller must be connected to the FREECLK of the PHY.Note: If you set this bit to '1', the GUSB2PHYCFG.U2_FREECLK_EXISTS bit must be set to '0'. Reset Source: rst_mod_g_rst_n
  [21:8] GFLADJ_REFCLK_FLADJ rw — This field indicates the frame length adjustment to be applied when SOF/ITP counter is running on the ref_clk. This register value is used to adjust the ITP interval when GCTL[SOFITPSYNC] is set to '1'. SOF and ITP interval when GLADJ.GFLADJ_REFCLK_LPM_SEL is set to '1'.This field must be programmed to a non-zero value only if GFLADJ_REFCLK_LPM_SEL is set to '1' or GCTL.SOFITPSYNC is set to '1'.The value is derived as follows:FLADJ_REF_CLK_FLADJ=[[125000/ref_clk_period_integer]-[125000/ref_clk_period]] * ref_clk_periodwhere - the ref_clk_period_integer is the integer value of the ref_clk period got by truncating the decimal [fractional] value that is programmed in the GUCTL.REF_CLK_PERIOD field. - the ref_clk_period is the ref_clk period including the fractional value.Examples:If the ref_clk is 24 MHz then - GUCTL.REF_CLK_PERIOD = 41 - GFLADJ.GLADJ_REFCLK_FLADJ = [[125000/41]-[125000/41.6666]]*41.6666 = 2032 [ignoring the fractional value]If the ref_clk is 48 MHz then - GUCTL.REF_CLK_PERIOD = 20 - GFLADJ.GLADJ_REFCLK_FLADJ = [[125000/20]-[125000/20.8333]]*20.8333 = 5208 [ignoring the fractional value] Reset Source: rst_mod_g_rst_n
  [7] GFLADJ_30MHZ_SDBND_SEL rw — GFLADJ_30MHZ_SDBND_SELThis field selects whether to use the input signal fladj_30mhz_reg or the GFLADJ.GFLADJ_30MHZ to adjust the frame length for the SOF/ITP.When this bit is set to, - 1, the controller uses the register field GFLADJ.GFLADJ_30MHZ value - 0, the controller uses the input signal fladj_30mhz_reg value Reset Source: rst_mod_g_rst_n
  [5:0] GFLADJ_30MHZ rw — GFLADJ_30MHZThis field indicates the value that is used for frame length adjustment instead of considering from the sideband input signal fladj_30mhz_reg. This enables post-silicon frame length adjustment in case the input signal fladj_30mhz_reg is connected to a wrong value or is not valid. For details on how to set this value, refer to section 5.2.4, 'Frame Length Adjustment Register [FLADJ],' of the xHCI Specification. Reset Source: rst_mod_g_rst_n
0x540 USB2SS_GBL_GRHB access not given reset not defined
0x540 USB2SS_GBL_GRHB_GUSB2RHBCTL — Global USB 2.0 Root Hub Control RegisterThe application must program this register before starting any transactions on the USB if a non-default value is desired.In Host mode, per-port registers are implemented.
  [3:0] OVRD_L1TIMEOUT — Overriding the driver programmed L1TIMEOUT value.If this value is 0, the L1 Timeout value is taken from the xHCI PORTHLPMC register. If this value is non-0, then this will override the L1 Timeout value programmed in the xHCI PORTHLPMC register. In that case the actual L1 Timeout would be 2 ^ <OVRD_L1TIMEOUT-1> * 8us. [1=8us, 2=16us, 3=32us etc] Reset Source: rst_mod_g_rst_n
